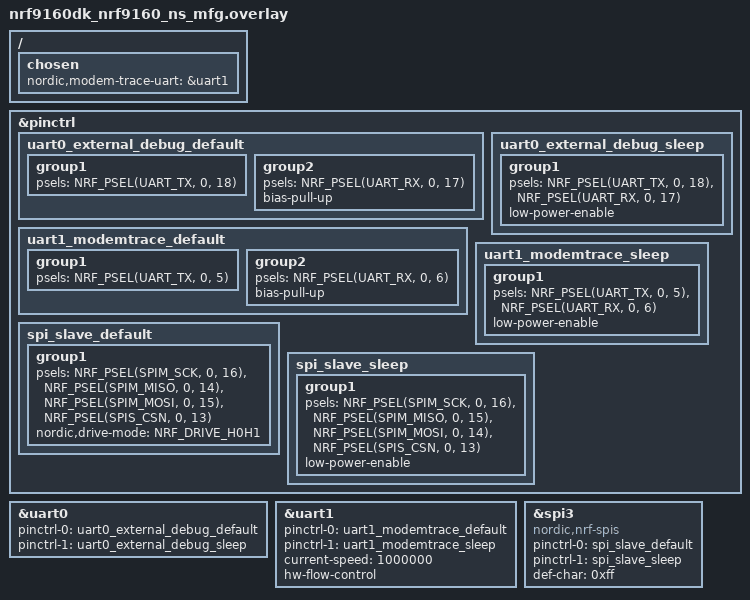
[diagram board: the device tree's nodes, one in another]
/*
 * Copyright (c) 2023 Nordic Semiconductor ASA
 *
 * SPDX-License-Identifier: LicenseRef-Nordic-5-Clause
 */

&pinctrl {
	uart0_external_debug_default: uart0_external_debug_default {
			group1 {
					psels = <NRF_PSEL(UART_TX, 0, 18)>;
			};
			group2 {
					psels = <NRF_PSEL(UART_RX, 0, 17)>;
					bias-pull-up;
			};
			/delete-property/ hw-flow-control;
	};

	uart0_external_debug_sleep: uart0_external_debug_sleep {
			group1 {
					psels = <NRF_PSEL(UART_TX, 0, 18)>,
							<NRF_PSEL(UART_RX, 0, 17)>;
					low-power-enable;
					/delete-property/ hw-flow-control;
			};
	};

	uart1_modemtrace_default: uart1_modemtrace_default {
		group1 {
				psels = <NRF_PSEL(UART_TX, 0, 5)>;
		};
		group2 {
				psels = <NRF_PSEL(UART_RX, 0, 6)>;
				bias-pull-up;
		};
		/delete-property/ hw-flow-control;
	};

	uart1_modemtrace_sleep: uart1_modemtrace_sleep {
			group1 {
					psels = <NRF_PSEL(UART_TX, 0, 5)>,
							<NRF_PSEL(UART_RX, 0, 6)>;
					low-power-enable;
					/delete-property/ hw-flow-control;
			};
	};

	spi_slave_default: spi_slave_default {
		group1 {
				psels = <NRF_PSEL(SPIM_SCK, 0, 16)>,
						<NRF_PSEL(SPIM_MISO, 0, 14)>,
						<NRF_PSEL(SPIM_MOSI, 0, 15)>,
						<NRF_PSEL(SPIS_CSN, 0, 13)>;
				nordic,drive-mode = <NRF_DRIVE_H0H1>;
		};
	};

	spi_slave_sleep: spi_slave_sleep {
		group1 {
				psels = <NRF_PSEL(SPIM_SCK, 0, 16)>,
						<NRF_PSEL(SPIM_MISO, 0, 15)>,
						<NRF_PSEL(SPIM_MOSI, 0, 14)>,
						<NRF_PSEL(SPIS_CSN, 0, 13)>;
				low-power-enable;
		};
	};
};

/* AT command interface - set to  uart0_external_debug_default for external header pins or uart0_netapp_default */
&uart0 {
	status = "okay";
	pinctrl-0 = <&uart0_external_debug_default>;
	pinctrl-1 = <&uart0_external_debug_sleep>;
	pinctrl-names = "default", "sleep";
};

/* Enable uart1 for tracing. */
&uart1 {
	status = "okay";
	pinctrl-0 = <&uart1_modemtrace_default>;
	pinctrl-1 = <&uart1_modemtrace_sleep>;
	current-speed = < 1000000 >;
	hw-flow-control;
};

&spi3 {
	compatible = "nordic,nrf-spis";
	/* status = "okay"; */
	pinctrl-0 = <&spi_slave_default>;
	pinctrl-1 = <&spi_slave_sleep>;
	pinctrl-names = "default", "sleep";
	def-char = <0xff>;
};

/ {
	chosen {
		nordic,modem-trace-uart = &uart1;
	};
};
